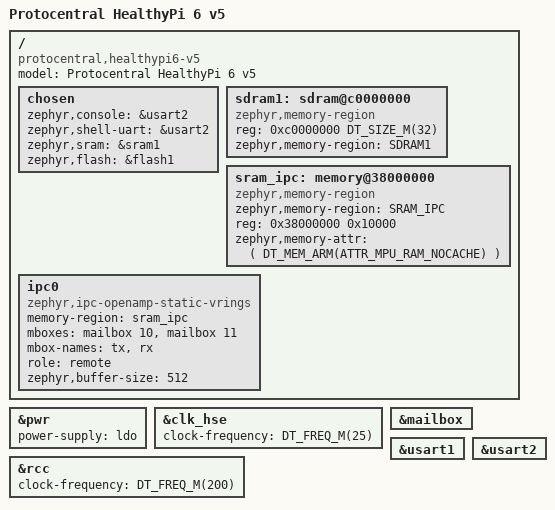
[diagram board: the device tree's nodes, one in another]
/*
 * Copyright (c) 2019 Linaro Limited
 * Copyright (c) 2025-2026 ProtoCentral
 *
 * SPDX-License-Identifier: Apache-2.0
 */

/dts-v1/;
#include <st/h7/stm32h757Xi_m4.dtsi>
#include <st/h7/stm32h757bitx-pinctrl.dtsi>
#include "healthypi6_v5.dtsi"

/ {
	model = "Protocentral HealthyPi 6 v5";
	compatible = "protocentral,healthypi6-v5";

	/* HW resources are split between CM7 and CM4 */
	chosen {
		zephyr,console = &usart2;
		zephyr,shell-uart = &usart2;
		zephyr,sram = &sram1;
		zephyr,flash = &flash1;
	};

	/* W9825G6KH SDRAM: single 32 MB chip on FMC Bank 0, shared with the M7.
	 *
	 * NOTE: there is NO SDRAM2 -- FMC Bank 1 (0xD0000000) is not connected.
	 * The M4 must touch SDRAM only after the M7 has initialized the FMC
	 * (covered by the 7 s boot delay).
	 */
	sdram1: sdram@c0000000 {
		compatible = "zephyr,memory-region", "mmio-sram";
		reg = <0xc0000000 DT_SIZE_M(32)>;
		zephyr,memory-region = "SDRAM1";
	};

	// IPC between CM7 and CM4 - OpenAMP/RPMSG Implementation
	// M4 role: "remote" (M7 is "host")
	sram_ipc: memory@38000000 {
		 zephyr,memory-region = "SRAM_IPC";
		 compatible = "zephyr,memory-region", "mmio-sram";
		 reg = <0x38000000 0x10000>;  // 64 KB total (full SRAM4)
		 zephyr,memory-attr = <( DT_MEM_ARM(ATTR_MPU_RAM_NOCACHE) )>;
	 };

	ipc0: ipc0 {
		compatible = "zephyr,ipc-openamp-static-vrings";
		memory-region = <&sram_ipc>;
		mboxes = <&mailbox 10>, <&mailbox 11>;
		mbox-names = "tx", "rx";
		role = "remote";  // M4 is OpenAMP remote, M7 is host
		zephyr,buffer-size = <512>;  // Must match M7 configuration
		status = "okay";
	};
};

/* Must match M7 power supply configuration (M7 controls hardware).
 * v5 board uses LDO-only mode (SMPS disabled) — see M7 DTS for rationale.
 */
&pwr {
	power-supply = "ldo";
};

&clk_hse {
	clock-frequency = <DT_FREQ_M(25)>;
	status = "okay";
};

&rcc {
	clock-frequency = <DT_FREQ_M(200)>;
};

&mailbox {
	status = "okay";
};

&usart1 {
	status = "okay";
};

&usart2 {
	status = "okay";
};
